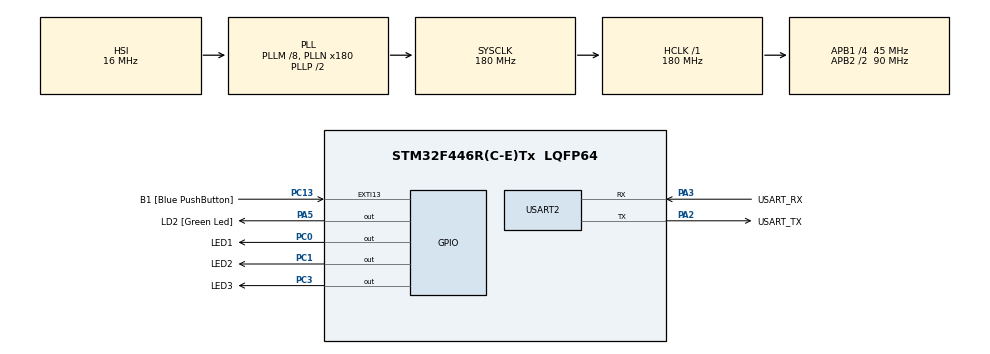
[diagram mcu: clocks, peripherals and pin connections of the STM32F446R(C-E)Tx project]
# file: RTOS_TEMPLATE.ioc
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FREERTOS.Tasks01=defaultTask,0,128,StartDefaultTask,Default,NULL,Dynamic,NULL,NULL;myTask02,0,128,StartTask02,Default,NULL,Dynamic,NULL,NULL
Mcu.Family=STM32F4
Mcu.Name=STM32F446R(C-E)Tx
Mcu.Package=LQFP64
NVIC.PriorityGroup=NVIC_PRIORITYGROUP_4
NVIC.TIM2_IRQn=true\:0\:0\:false\:false\:true\:false\:false
NVIC.TimeBase=TIM2_IRQn
NVIC.TimeBaseIP=TIM2
PA13.GPIO_Label=TMS
PA13.Mode=Serial_Wire
PA13.Signal=SYS_JTMS-SWDIO
PA14.GPIO_Label=TCK
PA14.Mode=Serial_Wire
PA14.Signal=SYS_JTCK-SWCLK
PA2.GPIO_Label=USART_TX
PA2.Mode=Asynchronous
PA2.Signal=USART2_TX
PA3.GPIO_Label=USART_RX
PA3.Mode=Asynchronous
PA3.Signal=USART2_RX
PA5.GPIO_Label=LD2 [Green Led]
PA5.Signal=GPIO_Output
PB3.GPIO_Label=SWO
PB3.Signal=SYS_JTDO-SWO
PC0.GPIO_Label=LED1
PC0.Signal=GPIO_Output
PC1.GPIO_Label=LED2
PC1.Signal=GPIO_Output
PC13.GPIO_Label=B1 [Blue PushButton]
PC13.GPIO_ModeDefaultEXTI=GPIO_MODE_IT_FALLING
PC13.Signal=GPXTI13
PC14-OSC32_IN.Mode=LSE-External-Oscillator
PC14-OSC32_IN.Signal=RCC_OSC32_IN
PC15-OSC32_OUT.Mode=LSE-External-Oscillator
PC15-OSC32_OUT.Signal=RCC_OSC32_OUT
PC3.GPIO_Label=LED3
PC3.Signal=GPIO_Output
PH0-OSC_IN.Mode=HSE-External-Oscillator
PH0-OSC_IN.Signal=RCC_OSC_IN
PH1-OSC_OUT.Mode=HSE-External-Oscillator
PH1-OSC_OUT.Signal=RCC_OSC_OUT
ProjectManager.HeapSize=0x200
ProjectManager.StackSize=0x400
ProjectManager.TargetToolchain=SW4STM32
RCC.48MHZClocksFreq_Value=84000000
RCC.AHBFreq_Value=180000000
RCC.APB1CLKDivider=RCC_HCLK_DIV4
RCC.APB1Freq_Value=45000000
RCC.APB1TimFreq_Value=90000000
RCC.APB2CLKDivider=RCC_HCLK_DIV2
RCC.APB2Freq_Value=90000000
RCC.APB2TimFreq_Value=180000000
RCC.CortexFreq_Value=180000000
RCC.FLatency-AdvancedSettings=FLASH_LATENCY_5
RCC.HCLKFreq_Value=180000000
RCC.HSE_VALUE=8000000
RCC.HSI_VALUE=16000000
RCC.PLLM=8
RCC.PLLN=180
RCC.SYSCLKFreq_VALUE=180000000
RCC.SYSCLKSource=RCC_SYSCLKSOURCE_PLLCLK
RCC.USBFreq_Value=180000000
RCC.VCOOutputFreq_Value=360000000
USART2.VirtualMode=VM_ASYNC
VP_FREERTOS_VS_ENABLE.Mode=Enabled
VP_SYS_VS_tim2.Mode=TIM2
board=NUCLEO-F446RE

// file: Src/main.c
#include "main.h"
#include "stm32f4xx_hal.h"
#include "cmsis_os.h"

/* USER CODE BEGIN Includes */
char buff[]="hello world \n\r";
/* USER CODE END Includes */

UART_HandleTypeDef huart2;

osThreadId defaultTaskHandle;
osThreadId myTask02Handle;
osThreadId myTask03Handle;

/* USER CODE BEGIN PV */
/* Private variables ---------------------------------------------------------*/

/* USER CODE END PV */

void SystemClock_Config(void);
static void MX_GPIO_Init(void);
static void MX_USART2_UART_Init(void);
void StartDefaultTask(void const * argument);
void StartTask02(void const * argument);
void StartTask03(void const * argument);

int main(void)
{

	HAL_Init();

	SystemClock_Config();
	MX_GPIO_Init();
	MX_USART2_UART_Init();

	osThreadDef(defaultTask, StartDefaultTask, osPriorityNormal, 0, 128);
	defaultTaskHandle = osThreadCreate(osThread(defaultTask), NULL);

	/* definition and creation of myTask02 */
	osThreadDef(myTask02, StartTask02, osPriorityNormal, 0, 128);
	myTask02Handle = osThreadCreate(osThread(myTask02), NULL);

	/* definition and creation of myTask02 */
	osThreadDef(myTask03, StartTask03, osPriorityNormal, 0, 128);
	myTask03Handle = osThreadCreate(osThread(myTask03), NULL);

	/* Start scheduler */
	osKernelStart();

	/* We should never get here as control is now taken by the scheduler */

	/* Infinite loop */
	/* USER CODE BEGIN WHILE */
//	HAL_GPIO_WritePin(LED1_GPIO_Port,LED1_Pin,GPIO_PIN_SET);
//	HAL_GPIO_WritePin(LED2_GPIO_Port,LED2_Pin,GPIO_PIN_SET);
//	HAL_GPIO_WritePin(LED3_GPIO_Port,LED3_Pin,GPIO_PIN_SET);

	while (1)
	{

		/* USER CODE END WHILE */

	}

}

void SystemClock_Config(void)
{

	RCC_OscInitTypeDef RCC_OscInitStruct;
	RCC_ClkInitTypeDef RCC_ClkInitStruct;

	/**Configure the main internal regulator output voltage
	 */
	__HAL_RCC_PWR_CLK_ENABLE();

	__HAL_PWR_VOLTAGESCALING_CONFIG(PWR_REGULATOR_VOLTAGE_SCALE1);

	/**Initializes the CPU, AHB and APB busses clocks
	 */
	RCC_OscInitStruct.OscillatorType = RCC_OSCILLATORTYPE_HSI;
	RCC_OscInitStruct.HSIState = RCC_HSI_ON;
	RCC_OscInitStruct.HSICalibrationValue = 16;
	RCC_OscInitStruct.PLL.PLLState = RCC_PLL_ON;
	RCC_OscInitStruct.PLL.PLLSource = RCC_PLLSOURCE_HSI;
	RCC_OscInitStruct.PLL.PLLM = 8;
	RCC_OscInitStruct.PLL.PLLN = 180;
	RCC_OscInitStruct.PLL.PLLP = RCC_PLLP_DIV2;
	RCC_OscInitStruct.PLL.PLLQ = 2;
	RCC_OscInitStruct.PLL.PLLR = 2;
	if (HAL_RCC_OscConfig(&RCC_OscInitStruct) != HAL_OK)
	{
		_Error_Handler(__FILE__, __LINE__);
	}

	/**Activate the Over-Drive mode
	 */
	if (HAL_PWREx_EnableOverDrive() != HAL_OK)
	{
		_Error_Handler(__FILE__, __LINE__);
	}

	/**Initializes the CPU, AHB and APB busses clocks
	 */
	RCC_ClkInitStruct.ClockType = RCC_CLOCKTYPE_HCLK|RCC_CLOCKTYPE_SYSCLK
			|RCC_CLOCKTYPE_PCLK1|RCC_CLOCKTYPE_PCLK2;
	RCC_ClkInitStruct.SYSCLKSource = RCC_SYSCLKSOURCE_PLLCLK;
	RCC_ClkInitStruct.AHBCLKDivider = RCC_SYSCLK_DIV1;
	RCC_ClkInitStruct.APB1CLKDivider = RCC_HCLK_DIV4;
	RCC_ClkInitStruct.APB2CLKDivider = RCC_HCLK_DIV2;

	if (HAL_RCC_ClockConfig(&RCC_ClkInitStruct, FLASH_LATENCY_5) != HAL_OK)
	{
		_Error_Handler(__FILE__, __LINE__);
	}

	/**Configure the Systick interrupt time
	 */
	HAL_SYSTICK_Config(HAL_RCC_GetHCLKFreq()/1000);

	/**Configure the Systick
	 */
	HAL_SYSTICK_CLKSourceConfig(SYSTICK_CLKSOURCE_HCLK);

	/* SysTick_IRQn interrupt configuration */
	HAL_NVIC_SetPriority(SysTick_IRQn, 15, 0);
}

/* USART2 init function */
static void MX_USART2_UART_Init(void)
{

	huart2.Instance = USART2;
	huart2.Init.BaudRate = 115200;
	huart2.Init.WordLength = UART_WORDLENGTH_8B;
	huart2.Init.StopBits = UART_STOPBITS_1;
	huart2.Init.Parity = UART_PARITY_NONE;
	huart2.Init.Mode = UART_MODE_TX_RX;
	huart2.Init.HwFlowCtl = UART_HWCONTROL_NONE;
	huart2.Init.OverSampling = UART_OVERSAMPLING_16;
	if (HAL_UART_Init(&huart2) != HAL_OK)
	{
		_Error_Handler(__FILE__, __LINE__);
	}

}

/** Configure pins as
 * Analog
 * Input
 * Output
 * EVENT_OUT
 * EXTI
 */
static void MX_GPIO_Init(void)
{

	GPIO_InitTypeDef GPIO_InitStruct;

	/* GPIO Ports Clock Enable */
	__HAL_RCC_GPIOC_CLK_ENABLE();
	__HAL_RCC_GPIOH_CLK_ENABLE();
	__HAL_RCC_GPIOA_CLK_ENABLE();
	__HAL_RCC_GPIOB_CLK_ENABLE();

	/*Configure GPIO pin Output Level */
	HAL_GPIO_WritePin(GPIOC, LED1_Pin|LED2_Pin|LED3_Pin, GPIO_PIN_RESET);

	/*Configure GPIO pin Output Level */
	HAL_GPIO_WritePin(LD2_GPIO_Port, LD2_Pin, GPIO_PIN_RESET);

	/*Configure GPIO pin : B1_Pin */
	GPIO_InitStruct.Pin = B1_Pin;
	GPIO_InitStruct.Mode = GPIO_MODE_IT_FALLING;
	GPIO_InitStruct.Pull = GPIO_NOPULL;
	HAL_GPIO_Init(B1_GPIO_Port, &GPIO_InitStruct);

	/*Configure GPIO pins : LED1_Pin LED2_Pin LED3_Pin */
	GPIO_InitStruct.Pin = LED1_Pin|LED2_Pin|LED3_Pin;
	GPIO_InitStruct.Mode = GPIO_MODE_OUTPUT_PP;
	GPIO_InitStruct.Pull = GPIO_NOPULL;
	GPIO_InitStruct.Speed = GPIO_SPEED_FREQ_LOW;
	HAL_GPIO_Init(GPIOC, &GPIO_InitStruct);

	/*Configure GPIO pin : LD2_Pin */
	GPIO_InitStruct.Pin = LD2_Pin;
	GPIO_InitStruct.Mode = GPIO_MODE_OUTPUT_PP;
	GPIO_InitStruct.Pull = GPIO_NOPULL;
	GPIO_InitStruct.Speed = GPIO_SPEED_FREQ_LOW;
	HAL_GPIO_Init(LD2_GPIO_Port, &GPIO_InitStruct);

}

/* StartDefaultTask function */
void StartDefaultTask(void const * argument)
{

	/* USER CODE BEGIN 5 */
	/* Infinite loop */
	for(;;)
	{
		HAL_GPIO_TogglePin(LED1_GPIO_Port,LED1_Pin);
		osDelay(100);
	}
	/* USER CODE END 5 */
}

/* StartTask02 function */
void StartTask02(void const * argument)
{
	/* USER CODE BEGIN StartTask02 */
	/* Infinite loop */
	for(;;)
	{
		HAL_GPIO_TogglePin(LED2_GPIO_Port,LED2_Pin);
		osDelay(1000);
	}
	/* USER CODE END StartTask02 */
}

void StartTask03(void const * argument){
	for(;;)
	{
		if (HAL_GPIO_ReadPin(B1_GPIO_Port,B1_Pin)== GPIO_PIN_RESET){
			HAL_GPIO_WritePin(LED3_GPIO_Port,LED3_Pin,GPIO_PIN_RESET);
			HAL_UART_Transmit(&huart2,(uint8_t*)buff,sizeof(buff),1000);
			osDelay(1000);
			HAL_GPIO_WritePin(LED3_GPIO_Port,LED3_Pin,GPIO_PIN_SET);

		} else {
			osDelay(1);
		}

	}
}

void HAL_TIM_PeriodElapsedCallback(TIM_HandleTypeDef *htim)
{
	if (htim->Instance == TIM2) {
		HAL_IncTick();
	}
}

void _Error_Handler(char *file, int line)
{
	while(1)
	{
	}
}

/************************ (C) COPYRIGHT STMicroelectronics *****END OF FILE****/
